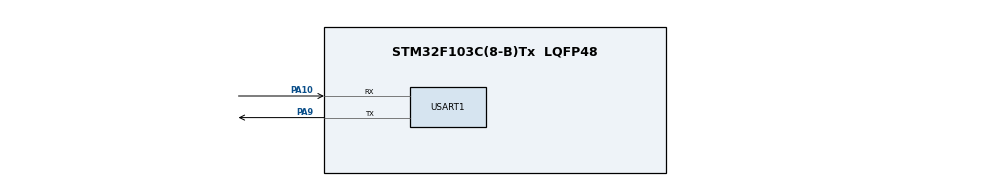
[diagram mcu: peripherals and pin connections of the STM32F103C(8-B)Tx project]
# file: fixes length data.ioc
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Mcu.Family=STM32F1
Mcu.Name=STM32F103C(8-B)Tx
Mcu.Package=LQFP48
NVIC.PriorityGroup=NVIC_PRIORITYGROUP_4
NVIC.TIM1_UP_IRQn=true\:0\:0\:true\:false\:true\:true\:true\:true
NVIC.USART1_IRQn=true\:1\:0\:true\:false\:true\:true\:true\:true
PA10.Mode=Asynchronous
PA10.Signal=USART1_RX
PA13.Mode=Serial_Wire
PA13.Signal=SYS_JTMS-SWDIO
PA14.Mode=Serial_Wire
PA14.Signal=SYS_JTCK-SWCLK
PA9.Mode=Asynchronous
PA9.Signal=USART1_TX
ProjectManager.HeapSize=0x200
ProjectManager.StackSize=0x400
ProjectManager.TargetToolchain=MDK-ARM V5.32
RCC.APB1Freq_Value=8000000
RCC.APB2Freq_Value=8000000
TIM1.AutoReloadPreload=TIM_AUTORELOAD_PRELOAD_ENABLE
TIM1.Period=1000-1
TIM1.Prescaler=8000-1
USART1.VirtualMode=VM_ASYNC
VP_TIM1_VS_ClockSourceINT.Mode=Internal
board=custom

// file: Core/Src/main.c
/* USER CODE BEGIN Header */
/**
  ******************************************************************************
  * @file           : main.c
  * @brief          : Main program body
  ******************************************************************************
  * @attention
  *
  * Copyright (c) 2025 STMicroelectronics.
  * All rights reserved.
  *
  * This software is licensed under terms that can be found in the LICENSE file
  * in the root directory of this software component.
  * If no LICENSE file comes with this software, it is provided AS-IS.
  *
  ******************************************************************************
  */
/* USER CODE END Header */
#include "main.h"

/* USER CODE BEGIN Includes */
#include <stdio.h>
#include <string.h>
/* USER CODE END Includes */

TIM_HandleTypeDef htim1;

UART_HandleTypeDef huart1;

/* USER CODE BEGIN PV */
static uint8_t rev_it_buf[6] = {0};
static char send_it_buf[32] = {0};
static uint8_t cnt = 0; //count
static uint8_t temp_data;
static uint8_t hour;
static uint8_t minute;
static uint8_t send_len;
static uint8_t tim_flag = 0;//delay one second
/* USER CODE END PV */

void SystemClock_Config(void);
static void MX_GPIO_Init(void);
static void MX_USART1_UART_Init(void);
static void MX_TIM1_Init(void);

int main(void)
{

  /* MCU Configuration--------------------------------------------------------*/

  /* Reset of all peripherals, Initializes the Flash interface and the Systick. */
  HAL_Init();

  /* Configure the system clock */
  SystemClock_Config();

  /* Initialize all configured peripherals */
  MX_GPIO_Init();
  MX_USART1_UART_Init();
  MX_TIM1_Init();
  /* USER CODE BEGIN 2 */
HAL_UART_Receive_IT(&huart1,&temp_data,1);
  /* USER CODE END 2 */

  /* Infinite loop */
  while (1)
  {

  }
}

void SystemClock_Config(void)
{
  RCC_OscInitTypeDef RCC_OscInitStruct = {0};
  RCC_ClkInitTypeDef RCC_ClkInitStruct = {0};

  /** Initializes the RCC Oscillators according to the specified parameters
  * in the RCC_OscInitTypeDef structure.
  */
  RCC_OscInitStruct.OscillatorType = RCC_OSCILLATORTYPE_HSI;
  RCC_OscInitStruct.HSIState = RCC_HSI_ON;
  RCC_OscInitStruct.HSICalibrationValue = RCC_HSICALIBRATION_DEFAULT;
  RCC_OscInitStruct.PLL.PLLState = RCC_PLL_NONE;
  if (HAL_RCC_OscConfig(&RCC_OscInitStruct) != HAL_OK)
  {
    Error_Handler();
  }

  /** Initializes the CPU, AHB and APB buses clocks
  */
  RCC_ClkInitStruct.ClockType = RCC_CLOCKTYPE_HCLK|RCC_CLOCKTYPE_SYSCLK
                              |RCC_CLOCKTYPE_PCLK1|RCC_CLOCKTYPE_PCLK2;
  RCC_ClkInitStruct.SYSCLKSource = RCC_SYSCLKSOURCE_HSI;
  RCC_ClkInitStruct.AHBCLKDivider = RCC_SYSCLK_DIV1;
  RCC_ClkInitStruct.APB1CLKDivider = RCC_HCLK_DIV1;
  RCC_ClkInitStruct.APB2CLKDivider = RCC_HCLK_DIV1;

  if (HAL_RCC_ClockConfig(&RCC_ClkInitStruct, FLASH_LATENCY_0) != HAL_OK)
  {
    Error_Handler();
  }
}

static void MX_TIM1_Init(void)
{

  TIM_ClockConfigTypeDef sClockSourceConfig = {0};
  TIM_MasterConfigTypeDef sMasterConfig = {0};

  htim1.Instance = TIM1;
  htim1.Init.Prescaler = 8000-1;
  htim1.Init.CounterMode = TIM_COUNTERMODE_UP;
  htim1.Init.Period = 1000-1;
  htim1.Init.ClockDivision = TIM_CLOCKDIVISION_DIV1;
  htim1.Init.RepetitionCounter = 0;
  htim1.Init.AutoReloadPreload = TIM_AUTORELOAD_PRELOAD_ENABLE;
  if (HAL_TIM_Base_Init(&htim1) != HAL_OK)
  {
    Error_Handler();
  }
  sClockSourceConfig.ClockSource = TIM_CLOCKSOURCE_INTERNAL;
  if (HAL_TIM_ConfigClockSource(&htim1, &sClockSourceConfig) != HAL_OK)
  {
    Error_Handler();
  }
  sMasterConfig.MasterOutputTrigger = TIM_TRGO_RESET;
  sMasterConfig.MasterSlaveMode = TIM_MASTERSLAVEMODE_DISABLE;
  if (HAL_TIMEx_MasterConfigSynchronization(&htim1, &sMasterConfig) != HAL_OK)
  {
    Error_Handler();
  }

}

static void MX_USART1_UART_Init(void)
{

  huart1.Instance = USART1;
  huart1.Init.BaudRate = 115200;
  huart1.Init.WordLength = UART_WORDLENGTH_8B;
  huart1.Init.StopBits = UART_STOPBITS_1;
  huart1.Init.Parity = UART_PARITY_NONE;
  huart1.Init.Mode = UART_MODE_TX_RX;
  huart1.Init.HwFlowCtl = UART_HWCONTROL_NONE;
  huart1.Init.OverSampling = UART_OVERSAMPLING_16;
  if (HAL_UART_Init(&huart1) != HAL_OK)
  {
    Error_Handler();
  }

}

static void MX_GPIO_Init(void)
{

  /* GPIO Ports Clock Enable */
  __HAL_RCC_GPIOA_CLK_ENABLE();

}

/* USER CODE BEGIN 4 */
void HAL_UART_RxCpltCallback(UART_HandleTypeDef *huart)
{
    if (huart == &huart1)
    {
			if (cnt <= 5)
			{
				rev_it_buf[cnt] = temp_data;
				cnt++;

			}
			if (cnt >= 6)
			{
				if (rev_it_buf[0] == 0xAA && rev_it_buf[1] == 0xBB && rev_it_buf[4] == 0x0D && rev_it_buf[5] == 0x0E)
				{
					hour = rev_it_buf[2];
					minute = rev_it_buf[3];
					tim_flag = 1;
				}
				else
				{
					tim_flag = 0;
				}

				HAL_TIM_Base_Start_IT(&htim1);
				memset(rev_it_buf,0,sizeof(rev_it_buf));
			}
			HAL_UART_Receive_IT(&huart1,&temp_data,1);
		}
}
void HAL_TIM_PeriodElapsedCallback(TIM_HandleTypeDef *htim)
{
		if (htim == &htim1)
		{
			HAL_TIM_Base_Stop_IT(&htim1);
			if (tim_flag == 1)
        {
            send_len = sprintf(send_it_buf, "AB %02d:%02d 要和我组乐队吗？\r\n", hour, minute);
            HAL_UART_Transmit_IT(&huart1, (uint8_t *)send_it_buf, send_len);
						tim_flag = 0;
        }
			else
				{
					char err[7] = "ERROR\r\n";
					HAL_UART_Transmit_IT(&huart1,(uint8_t *)err,7);
				}
			cnt = 0;
			HAL_UART_Receive_IT(&huart1, &temp_data, 1);
    }
}
/* USER CODE END 4 */

void Error_Handler(void)
{
  __disable_irq();
  while (1)
  {
  }
}
